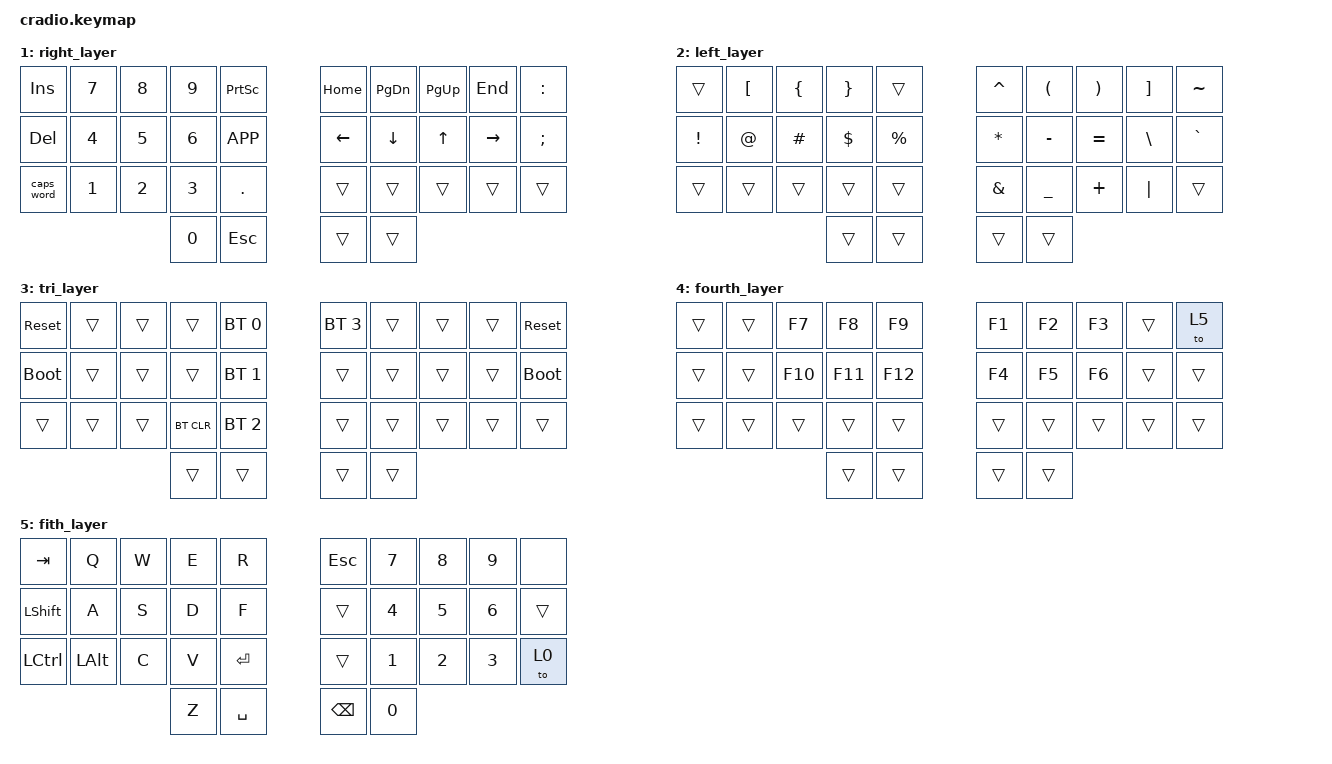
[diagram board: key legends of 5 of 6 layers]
// Copyright (c) 2022 The ZMK Contributors
// SPDX-License-Identifier: MIT

#include <behaviors.dtsi>
#include <dt-bindings/zmk/keys.h>
#include <dt-bindings/zmk/bt.h>

// Home row mods macro
#define HRML(k1,k2,k3,k4) &ht LSHFT k1  &ht LALT k2  &ht LCTRL k3  &ht LGUI k4
#define HRMR(k1,k2,k3,k4) &ht RGUI k1  &ht RCTRL k2  &ht RALT k3  &ht RSHFT k4

/ {
    behaviors {
        ht: hold_tap {
            compatible = "zmk,behavior-hold-tap";
            #binding-cells = <2>;
            flavor = "tap-preferred";
            tapping-term-ms = <220>;
            quick-tap-ms = <150>;
            require-prior-idle-ms = <50>;
            bindings = <&kp>, <&kp>;
        };
    };

    conditional_layers {
        compatible = "zmk,conditional-layers";
        tri_layer {
            if-layers = <1 2>;
            then-layer = <3>;
        };
    };

    keymap {
        compatible = "zmk,keymap";
        default_layer {
            bindings = <
        //╭──────────┬──────────┬──────────┬──────────┬──────────╮   ╭──────────┬──────────┬──────────┬──────────┬──────────╮
        //│  Q       │  W       │  E       │  R       │  T       │   │  Y       │  U       │  I       │  O       │  P       │
            &kp Q      &kp W      &kp E      &kp R      &kp T          &kp Y      &kp U      &kp I      &kp O      &kp P
        //├──────────┼──────────┼──────────┼──────────┼──────────┤   ├──────────┼──────────┼──────────┼──────────┼──────────┤
        //│  A       │  S       │  D       │  F       │  G       │   │  H       │  J       │  K       │  L       │ ' "      │
            HRML(A,        S,         D,         F)     &kp G          &kp H      HRMR(J,        K,         L,        SQT)
        //├──────────┼──────────┼──────────┼──────────┼──────────┤   ├──────────┼──────────┼──────────┼──────────┼──────────┤
        //│  Z       │  X       │  C       │  V       │  B       │   │  N       │  M       │ , <      │ . >      │ / ?      │
            &kp Z      &kp X      &kp C      &kp V      &kp B          &kp N      &kp M      &kp COMMA  &kp DOT    &kp FSLH
        //╰──────────┴──────────┴──────────┼──────────┼──────────┤   ├──────────┼──────────┼──────────┴──────────┴──────────╯
                                            &lt 2 TAB   &lt 4 ENTER     &kp SPACE  &lt 1 BSPC
        //                                 ╰──────────┴──────────╯   ╰──────────┴──────────╯
            >;
        };

        right_layer {
            bindings = <
        //╭──────────┬──────────┬──────────┬──────────┬───────────╮        ╭──────────┬──────────┬──────────┬──────────┬──────────╮
        //│ INSERT   │  7       │  8       │  9       │PRINTSCREEN│        │ HOME     │ PAGE DN  │ PAGE UP  │ END      │  :       │
            &kp INS    &kp N7     &kp N8     &kp N9     &kp PRINTSCREEN     &kp HOME   &kp PG_DN  &kp PG_UP  &kp END    &kp COLON
        //├──────────┼──────────┼──────────┼──────────┼───────────┤        ├──────────┼──────────┼──────────┼──────────┼──────────┤
        //│ DELETE   │  4       │  5       │  6       │ context m │        │ LEFT     │ DOWN     │ UP       │ RIGHT    │  ;       │
            &kp DEL    &kp N4     &kp N5     &kp N6     &kp K_APP              &kp LEFT   &kp DOWN   &kp UP   &kp RIGHT   &kp SEMI
        //├──────────┼──────────┼──────────┼──────────┼───────────┤        ├──────────┼──────────┼──────────┼──────────┼──────────┤
        //│ CAPS     │  1       │  2       │  3       │  .        │        │          │          │          │          │          │
           &caps_word  &kp N1     &kp N2     &kp N3     &kp DOT              &trans     &trans     &trans     &trans     &trans
        //╰──────────┴──────────┴──────────┼──────────┼───────────┤        ├──────────┼──────────┼──────────┴──────────┴──────────╯
                                             &kp N0     &kp ESC             &trans     &trans
        //                                 ╰──────────┴───────────╯        ╰──────────┴──────────╯
            >;
        };

        left_layer {
            bindings = <
        //╭──────────┬──────────┬──────────┬──────────┬──────────╮   ╭──────────┬──────────┬──────────┬──────────┬──────────╮
        //│          │  [       │  {       │  }       │          │   │  ^       │  (       │  )       │  ]       │  ~       │
            &trans     &kp LBKT   &kp LBRC   &kp RBRC   &trans         &kp CARET  &kp LPAR   &kp RPAR   &kp RBKT   &kp TILDE
        //├──────────┼──────────┼──────────┼──────────┼──────────┤   ├──────────┼──────────┼──────────┼──────────┼──────────┤
        //│  !       │  @       │  #       │  $       │  %       │   │  *       │  -       │  =       │  \       │  `       │
            &kp EXCL   &kp AT     &kp HASH   &kp DLLR   &kp PRCNT      &kp ASTRK  &kp MINUS  &kp EQUAL  &kp BSLH   &kp GRAVE
        //├──────────┼──────────┼──────────┼──────────┼──────────┤   ├──────────┼──────────┼──────────┼──────────┼──────────┤
        //│          │          │          │          │          │   │  &       │  _       │  +       │  │       │          │
            &trans     &trans     &trans     &trans     &trans         &kp AMPS   &kp UNDER  &kp PLUS   &kp PIPE   &trans
        //╰──────────┴──────────┴──────────┼──────────┼──────────┤   ├──────────┼──────────┼──────────┴──────────┴──────────╯
                                             &trans     &trans         &trans     &trans
        //                                 ╰──────────┴──────────╯   ╰──────────┴──────────╯
            >;
        };

        tri_layer {
            bindings = <
        //╭──────────┬──────────┬──────────┬──────────┬──────────╮   ╭──────────┬──────────┬──────────┬──────────┬──────────╮
        //│ RESET    │          │          │          │PROFILE 0 │   │          │          │          │          │  RESET   │
           &sys_reset  &trans     &trans     &trans    &bt BT_SEL 0  &bt BT_SEL 3   &trans   &trans     &trans    &sys_reset
        //├──────────┼──────────┼──────────┼──────────┼──────────┤   ├──────────┼──────────┼──────────┼──────────┼──────────┤
        //│BOOTLOADER│          │          │          │PROFILE 1 │   │          │          │          │          │BOOTLOADER│
          &bootloader  &trans     &trans     &trans    &bt BT_SEL 1    &trans     &trans     &trans     &trans    &bootloader
        //├──────────┼──────────┼──────────┼──────────┼──────────┤   ├──────────┼──────────┼──────────┼──────────┼──────────┤
        //│          │          │          │ CLEAR BT │PROFILE 2 │   │          │          │          │          │          │
            &trans     &trans     &trans    &bt BT_CLR &bt BT_SEL 2    &trans     &trans     &trans     &trans     &trans
        //╰──────────┴──────────┴──────────┼──────────┼──────────┤   ├──────────┼──────────┼──────────┴──────────┴──────────╯
                                             &trans     &trans         &trans     &trans
        //                                 ╰──────────┴──────────╯   ╰──────────┴──────────╯
            >;
        };

        fourth_layer {
            bindings = <
        //╭──────────┬──────────┬──────────┬──────────┬──────────╮   ╭──────────┬──────────┬──────────┬──────────┬──────────╮
        //│          │          │    F7    │    F8    │    F9    │   │    F1    │    F2    │    F3    │          │          │
             &trans     &trans     &kp F7     &kp F8     &kp F9         &kp F1   &kp F2       &kp F3     &trans     &to 5
        //├──────────┼──────────┼──────────┼──────────┼──────────┤   ├──────────┼──────────┼──────────┼──────────┼──────────┤
        //           │          │    F10   │   F11    │   F12    │   │   F4     │   F5     │    F6    │          
             &trans    &trans     &kp F10     &kp F11    &kp F12           &kp F4     &kp F5     &kp F6     &trans      &trans
        //├──────────┼──────────┼──────────┼──────────┼──────────┤   ├──────────┼──────────┼──────────┼──────────┼──────────┤
        //│          │          │          │          │          │   │          │          │          │          │          │
            &trans     &trans     &trans      &trans    &trans         &trans     &trans     &trans     &trans     &trans
        //╰──────────┴──────────┴──────────┼──────────┼──────────┤   ├──────────┼──────────┼──────────┴──────────┴──────────╯
                                             &trans     &trans         &trans     &trans
        //                                 ╰──────────┴──────────╯   ╰──────────┴──────────╯
            >;
        };  

        fith_layer {
            bindings = <
        //╭──────────┬──────────┬──────────┬──────────┬──────────╮   ╭──────────┬────────────┬──────────┬────────┬──────────╮
        //│    TAB   │    Q     │    W     │    E     │    R     │   │    ESC   │    7       │  8       │  9     │  nothing │
             &kp TAB     &kp Q      &kp W     &kp E       &kp R          &kp ESC    &kp N7     &kp N8     &kp N9      &none
        //├──────────┼──────────┼──────────┼──────────┼──────────┤   ├──────────┼────────────┼──────────┼─────── ┼──────────┤
        //           │     A    │    S     │    D     │     F    │   │          │    4       │  5       │  6     
            &kp LSHFT    &kp A       &kp S    &kp D       &kp F           &trans    &kp N4     &kp N5     &kp N6    &trans
        //├──────────┼──────────┼──────────┼──────────┼──────────┤   ├──────────┼────────────┼──────────┼─────── ┼──────────┤
        //│          │    LALT  │      C   │     V    │   ENTER  │   │          │    1       │  2       │  3     │ Layer 0  │
            &kp LCTRL  &kp LALT    &kp C     &kp V    &kp ENTER         &trans     &kp N1     &kp N2     &kp N3     &to 0
        //╰──────────┴──────────┴──────────┼──────────┼──────────┤   ├──────────┼──────────┼──────────┴──────────┴──────────╯
                                             &kp Z      &kp SPACE      &kp BSPC     &kp N0
        //                                 ╰──────────┴──────────╯   ╰──────────┴──────────╯
            >;
        };           
    };
};
